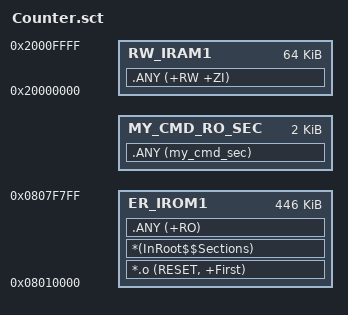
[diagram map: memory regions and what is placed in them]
; *************************************************************
; *** Scatter-Loading Description File generated by uVision ***
; *************************************************************

LR_IROM1 0x08010000 0x00070000  {    ; load region size_region
  ER_IROM1 0x08010000 0x00070000-0x800  {  ; load address = execution address
   *.o (RESET, +First)
   *(InRoot$$Sections)
   .ANY (+RO)
  }
  
; 分配命令存储空间
  MY_CMD_RO_SEC +0 0x800 {
   .ANY (my_cmd_sec)
  }
  
  RW_IRAM1 0x20000000 0x00010000  {  ; RW data
   .ANY (+RW +ZI)
  }
}

